# STM32H7S register map
File version: 1.4
CPU: CM7 r0p1, little endian, MPU, FPU, 4 interrupt priority bits
Registers are 32-bit, read-write, reset 0x0 unless marked. A register's access mark holds for its fields unless they carry their own. Offsets are from the block's base; [hi:lo] are bit positions; {n}, {i} and the like mark numbered series.

## CRC — Cyclic redundancy check calculation unit
Base 0x58024C00
0x00 CRC_DR reset 0xFFFFFFFF — CRC data register
  [31:0] DR — Data register bits This register is used to write new data to the CRC calculator. It holds the previous CRC calculation result when it is read. If the data size is less than 32 bits, the least significant bits are used to write/read the correct value.
0x04 CRC_IDR — CRC independent data register
  [31:0] IDR — General-purpose 32-bit data register bits These bits can be used as a temporary storage location for four bytes. This register is not affected by CRC resets generated by the RESET bit in the CRC_CR register
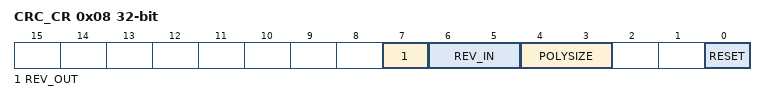
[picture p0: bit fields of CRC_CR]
0x08 CRC_CR — CRC control register
  [7] REV_OUT — Reverse output data This bit controls the reversal of the bit order of the output data.
    0=Bit order not affected; 1=Bit-reversed output format
  [6:5] REV_IN — Reverse input data This bitfield controls the reversal of the bit order of the input data
    0=Bit order not affected; 1=Bit reversal done by byte; 2=Bit reversal done by half-word; 3=Bit reversal done by word
  [4:3] POLYSIZE — Polynomial size These bits control the size of the polynomial.
    0=32 bit polynomial; 1=16 bit polynomial; 2=8 bit polynomial; 3=7 bit polynomial
  [0] RESET — RESET bit This bit is set by software to reset the CRC calculation unit and set the data register to the value stored in the CRC_INIT register. This bit can only be set, it is automatically cleared by hardware
0x10 CRC_INIT reset 0xFFFFFFFF — CRC initial value
  [31:0] CRC_INIT — Programmable initial CRC value This register is used to write the CRC initial value.
0x14 CRC_POL reset 0x4C11DB7 — CRC polynomial
  [31:0] POL — Programmable polynomial This register is used to write the coefficients of the polynomial to be used for CRC calculation. If the polynomial size is less than 32 bits, the least significant bits have to be used to program the correct value.

## DLYB1 — DLYB register block
Base 0x52008000
Same registers: DLYB2 0x48002800
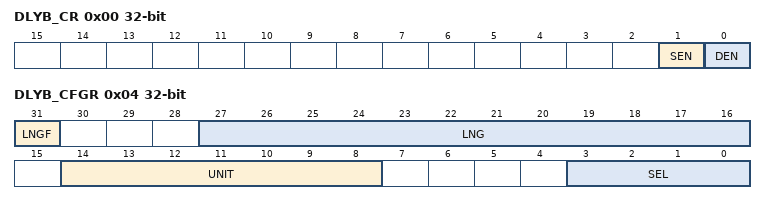
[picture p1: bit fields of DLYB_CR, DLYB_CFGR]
0x00 DLYB_CR — DLYB control register
  [1] SEN — Sampler length enable bit
    0=Sampler length and register access to UNIT[6:0] and SEL[3:0] disabled, output clock enabled; 1=Sampler length and register access to UNIT[6:0] and SEL[3:0] enabled, output clock disabled
  [0] DEN — Delay block enable bit
    0=DLYB disabled; 1=DLYB enabled
0x04 DLYB_CFGR access per field — DLYB configuration register
  [31] LNGF ro — Length valid flag This flag indicates when the delay line length value contained in LNG[11:0] is valid after UNIT[6:0] bits changed.
    0=Length value in LNG is not valid; 1=Length value in LNG is valid
  [27:16] LNG ro — Delay line length value These bits reflect the 12 unit delay values sampled at the rising edge of the input clock. The value is only valid when LNGF = 1.
  [14:8] UNIT rw — Delay of a unit delay cell. These bits can only be written when SEN = 1. Unit delay = initial delay + UNIT[6:0] x delay step
  [3:0] SEL rw — Phase for the output clock. These bits can only be written when SEN = 1. Output clock phase = input clock + SEL[3:0] x unit delay

## GFXMMU — Chrom-GRC
Base 0x52010000
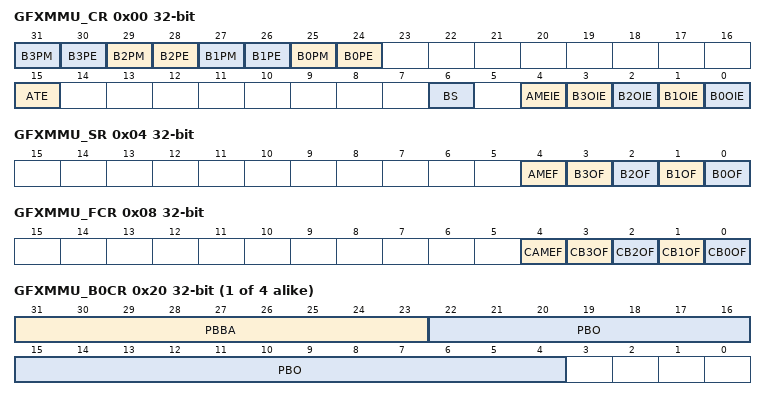
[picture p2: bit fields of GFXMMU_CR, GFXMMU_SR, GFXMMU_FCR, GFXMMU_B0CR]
0x00 GFXMMU_CR — GFXMMU configuration register
  [2n+25] B{n}PM (n=0..3) — Buffer {n} packing mode This bit selects the byte to be removed during packing operations on buffer {n}
    0=MSB is removed; 1=LSB is removed
  [2n+24] B{n}PE (n=0..3) — Buffer {n} packing enable This bit enables the packing on buffer {n}. The packing is functional only if the block size is configured in 12-byte mode. In 16-byte mode, this bit is ignored.
    0=Packing is disabled; 1=Packing is enable
  [15] ATE — Address translation enable This bit enables the address translation based on the values programmed in the LUT.
    0=Address translation is disable; 1=Address translation is enable
  [6] BS — Block size This bit defines the size of the blocks
    0=16-byte blocks; 1=12-byte blocks
  [4] AMEIE — AXI master error interrupt enable This bit enables the AXI master error interrupt.
    0=Interrupt disable; 1=Interrupt enabled
  [n] B{n}OIE (n=0..3) — Buffer {n} overflow interrupt enable This bit enables the buffer {n} overflow interrupt.
    0=Interrupt disable; 1=Interrupt enabled
0x04 GFXMMU_SR ro — GFXMMU status register
  [4] AMEF — AXI master error flag This bit is set when an AXI error happens during a transaction. It is cleared by writing 1 to CAMEF.
  [n] B{n}OF (n=0..3) — Buffer {n} overflow flag This bit is set when an overflow occurs during the offset calculation of the buffer {n}. It is cleared by writing 1 to CB{n}OF.
0x08 GFXMMU_FCR — GFXMMU flag clear register
  [4] CAMEF — Clear AXI master error flag Writing 1 clears the AXI master error flag in the GFXMMU_SR register.
  [n] CB{n}OF (n=0..3) — Clear buffer {n} overflow flag Writing 1 clears the buffer {n} overflow flag in the GFXMMU_SR register.
0x10 GFXMMU_DVR — GFXMMU default value register
  [31:0] DV — Default value This field indicates the default 32-bit value which is returned when a master accesses a virtual memory location not physically mapped.
0x14 GFXMMU_DAR — GFXMMU default alpha register
  [7:0] DA — Default alpha This field indicates the default 8-bit value which is merged with the 24-bit value when a master accesses a virtual memory location in packed mode.
{0x20+4i} GFXMMU_B{i}CR (i=0..3) — GFXMMU buffer {i} configuration register
  [31:23] PBBA — Physical buffer base address Base address MSB of the physical buffer.
  [22:4] PBO — Physical buffer offset Offset of the physical buffer.
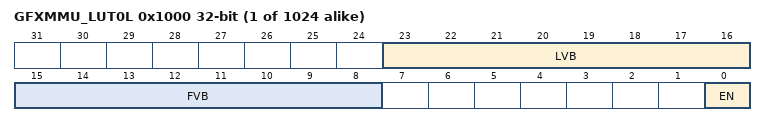
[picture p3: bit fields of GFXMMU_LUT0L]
{0x1000+8i} GFXMMU_LUT{i}L (i=0..1023) — GFXMMU LUT entry {i} low
  [23:16] LVB — Last valid block Number of the last valid block of line number X.
  [15:8] FVB — First valid block Number of the first valid block of line number x.
  [0] EN — Enable Line enable.
    0=Line is disabled (no MMU evaluation is performed); 1=Line is enabled (MMU evaluation is performed)
{0x1004+8i} GFXMMU_LUT{i}H (i=0..1023) — GFXMMU LUT entry {i} high
  [17:0] LO — Line offset Line offset of line number x expressed in number of blocks
